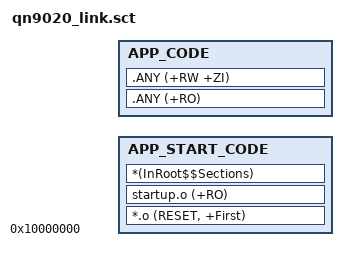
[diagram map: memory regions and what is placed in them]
; *************************************************************
; *** Scatter-Loading Description File generated by Quintic ***
; *************************************************************
LR_ROM1 0x10000000 0x10000  
{
   APP_START_CODE 0x10000000 
   {
     *.o (RESET, +First)
     startup.o (+RO)
     *(InRoot$$Sections)
   }
   
   APP_CODE +0
   {
     .ANY (+RO)
     .ANY (+RW +ZI)
   }
}

